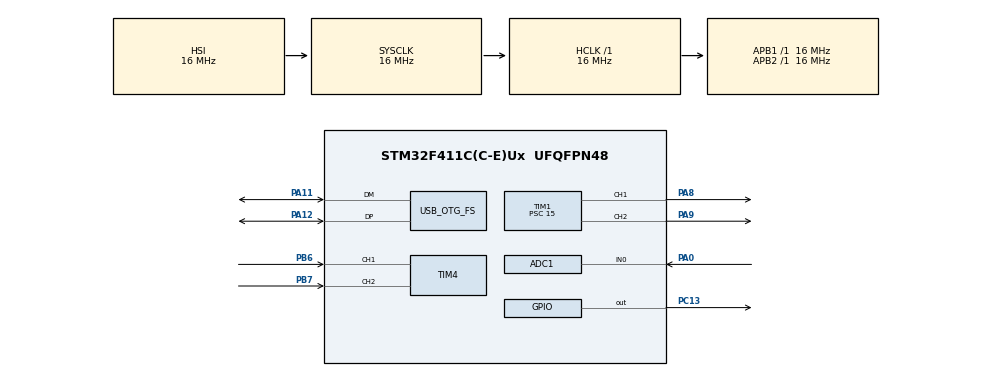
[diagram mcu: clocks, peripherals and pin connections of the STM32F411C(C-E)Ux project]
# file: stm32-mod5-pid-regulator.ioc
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ADC1.Channel-1\#ChannelRegularConversion=ADC_CHANNEL_0
ADC1.ClockPrescaler=ADC_CLOCK_SYNC_PCLK_DIV4
ADC1.NbrOfConversionFlag=1
ADC1.Rank-1\#ChannelRegularConversion=1
ADC1.SamplingTime-1\#ChannelRegularConversion=ADC_SAMPLETIME_84CYCLES
ADC1.master=1
Mcu.Family=STM32F4
Mcu.Name=STM32F411C(C-E)Ux
Mcu.Package=UFQFPN48
NVIC.OTG_FS_IRQn=true\:0\:0\:false\:false\:true\:false\:true\:true
NVIC.PriorityGroup=NVIC_PRIORITYGROUP_4
NVIC.TIM1_UP_TIM10_IRQn=true\:0\:0\:false\:false\:true\:true\:true\:true
PA0-WKUP.Signal=ADCx_IN0
PA11.Mode=Device_Only
PA11.Signal=USB_OTG_FS_DM
PA12.Mode=Device_Only
PA12.Signal=USB_OTG_FS_DP
PA8.Signal=S_TIM1_CH1
PA9.Signal=S_TIM1_CH2
PB6.GPIO_PuPd=GPIO_PULLUP
PB6.Signal=S_TIM4_CH1
PB7.GPIO_PuPd=GPIO_PULLUP
PB7.Signal=S_TIM4_CH2
PC13-ANTI_TAMP.Signal=GPIO_Output
PH0\ -\ OSC_IN.Mode=HSE-External-Oscillator
PH0\ -\ OSC_IN.Signal=RCC_OSC_IN
PH1\ -\ OSC_OUT.Mode=HSE-External-Oscillator
PH1\ -\ OSC_OUT.Signal=RCC_OSC_OUT
ProjectManager.HeapSize=0x200
ProjectManager.StackSize=0x400
ProjectManager.TargetToolchain=CMake
RCC.48MHZClocksFreq_Value=48000000
RCC.AHBFreq_Value=16000000
RCC.APB1Freq_Value=16000000
RCC.APB2Freq_Value=16000000
RCC.CortexFreq_Value=16000000
RCC.HSE_VALUE=25000000
RCC.HSI_VALUE=16000000
RCC.LSE_VALUE=32768
RCC.PLLM=15
RCC.PLLN=144
RCC.PLLQ=5
RCC.SYSCLKFreq_VALUE=16000000
RCC.VCOOutputFreq_Value=240000000
SH.ADCx_IN0.0=ADC1_IN0,IN0
SH.S_TIM1_CH1.0=TIM1_CH1,PWM Generation1 CH1
SH.S_TIM1_CH2.0=TIM1_CH2,PWM Generation2 CH2
SH.S_TIM4_CH1.0=TIM4_CH1,Encoder_Interface
SH.S_TIM4_CH2.0=TIM4_CH2,Encoder_Interface
TIM1.Channel-PWM\ Generation1\ CH1=TIM_CHANNEL_1
TIM1.Channel-PWM\ Generation2\ CH2=TIM_CHANNEL_2
TIM1.OCPolarity_1=TIM_OCPOLARITY_HIGH
TIM1.OCPolarity_2=TIM_OCPOLARITY_HIGH
TIM1.Period=999
TIM1.Prescaler=15
TIM10.Period=99
TIM10.Prescaler=1599
TIM4.EncoderMode=TIM_ENCODERMODE_TI12
TIM4.IC1Filter=8
TIM4.IC2Filter=8
USB_DEVICE.CLASS_NAME_FS=CDC
USB_DEVICE.VirtualMode=Cdc
USB_DEVICE.VirtualModeFS=Cdc_FS
USB_OTG_FS.VirtualMode=Device_Only
VP_TIM10_VS_ClockSourceINT.Mode=Enable_Timer
VP_USB_DEVICE_VS_USB_DEVICE_CDC_FS.Mode=CDC_FS
board=custom

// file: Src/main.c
/* USER CODE BEGIN Header */
/**
  ******************************************************************************
  * @file           : main.c
  * @brief          : Main program body
  ******************************************************************************
  * @attention
  *
  * Copyright (c) 2026 STMicroelectronics.
  * All rights reserved.
  *
  * This software is licensed under terms that can be found in the LICENSE file
  * in the root directory of this software component.
  * If no LICENSE file comes with this software, it is provided AS-IS.
  *
  ******************************************************************************
  */
/* USER CODE END Header */
#include "main.h"
#include "adc.h"
#include "tim.h"
#include "usb_device.h"
#include "gpio.h"

/* USER CODE BEGIN Includes */
#include "app.h"
/* USER CODE END Includes */

void SystemClock_Config(void);

int main(void)
{

  /* MCU Configuration--------------------------------------------------------*/

  /* Reset of all peripherals, Initializes the Flash interface and the Systick. */
  HAL_Init();

  /* Configure the system clock */
  SystemClock_Config();

  /* Initialize all configured peripherals */
  MX_GPIO_Init();
  MX_ADC1_Init();
  MX_TIM1_Init();
  MX_TIM4_Init();
  MX_TIM10_Init();
  MX_USB_DEVICE_Init();
  /* USER CODE BEGIN 2 */
  app_setup();
  app_main();
  /* USER CODE END 2 */

  /* Infinite loop */
  while (1)
  {

  }
}

void SystemClock_Config(void)
{
  RCC_OscInitTypeDef RCC_OscInitStruct = {0};
  RCC_ClkInitTypeDef RCC_ClkInitStruct = {0};

  /** Configure the main internal regulator output voltage
  */
  __HAL_RCC_PWR_CLK_ENABLE();
  __HAL_PWR_VOLTAGESCALING_CONFIG(PWR_REGULATOR_VOLTAGE_SCALE1);

  /** Initializes the RCC Oscillators according to the specified parameters
  * in the RCC_OscInitTypeDef structure.
  */
  RCC_OscInitStruct.OscillatorType = RCC_OSCILLATORTYPE_HSI|RCC_OSCILLATORTYPE_HSE;
  RCC_OscInitStruct.HSEState = RCC_HSE_ON;
  RCC_OscInitStruct.HSIState = RCC_HSI_ON;
  RCC_OscInitStruct.HSICalibrationValue = RCC_HSICALIBRATION_DEFAULT;
  RCC_OscInitStruct.PLL.PLLState = RCC_PLL_ON;
  RCC_OscInitStruct.PLL.PLLSource = RCC_PLLSOURCE_HSE;
  RCC_OscInitStruct.PLL.PLLM = 15;
  RCC_OscInitStruct.PLL.PLLN = 144;
  RCC_OscInitStruct.PLL.PLLP = RCC_PLLP_DIV2;
  RCC_OscInitStruct.PLL.PLLQ = 5;
  if (HAL_RCC_OscConfig(&RCC_OscInitStruct) != HAL_OK)
  {
    Error_Handler();
  }

  /** Initializes the CPU, AHB and APB buses clocks
  */
  RCC_ClkInitStruct.ClockType = RCC_CLOCKTYPE_HCLK|RCC_CLOCKTYPE_SYSCLK
                              |RCC_CLOCKTYPE_PCLK1|RCC_CLOCKTYPE_PCLK2;
  RCC_ClkInitStruct.SYSCLKSource = RCC_SYSCLKSOURCE_HSI;
  RCC_ClkInitStruct.AHBCLKDivider = RCC_SYSCLK_DIV1;
  RCC_ClkInitStruct.APB1CLKDivider = RCC_HCLK_DIV1;
  RCC_ClkInitStruct.APB2CLKDivider = RCC_HCLK_DIV1;

  if (HAL_RCC_ClockConfig(&RCC_ClkInitStruct, FLASH_LATENCY_0) != HAL_OK)
  {
    Error_Handler();
  }
}

void Error_Handler(void)
{
  __disable_irq();
  while (1)
  {
  }
}
